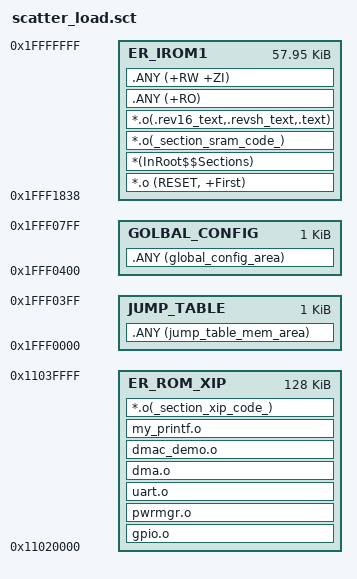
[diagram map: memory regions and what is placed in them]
; *************************************************************
; *** Scatter-Loading Description File generated by uVision ***
; *************************************************************

LR_IROM1 0x1fff1838 0x0000E7C8  {    ; load region size_region
  ER_IROM1 0x1fff1838 0x0000E7C8  {  ; load address = execution address
   *.o (RESET, +First)
   *(InRoot$$Sections)
   *.o(_section_sram_code_)
   *.o(.rev16_text,.revsh_text,.text)
   .ANY (+RO)
   .ANY (+RW +ZI)
  }
}
LR_IROM2  0x1fff0000 0x00800 {
  JUMP_TABLE 0x1fff0000 0x00400  {
   .ANY (jump_table_mem_area) 
	
  }
  GOLBAL_CONFIG 0x1fff0400 0x00400  {
   .ANY (global_config_area) 
	
  }  
} 
LR_ROM_XIP  0x11020000 0x020000 {
  ER_ROM_XIP 0x11020000 0x020000  {
	gpio.o
	pwrmgr.o
	uart.o
	dma.o
	dmac_demo.o
	my_printf.o	
  *.o(_section_xip_code_)
  }
} 



